# nrf54lv10a_enga_application register map
Vendor: Nordic Semiconductor; Series: nrf54l; File version: 1
CPU: CM33 r0p4, little endian, MPU, FPU, 3 interrupt priority bits, 270 interrupts, 4 SAU regions
Registers are 32-bit, read-write, reset 0x0 unless marked. A register's access mark holds for its fields unless they carry their own. Offsets are from the block's base; [hi:lo] are bit positions; lines under a group give offsets from that group; {n}, {i} and the like mark numbered series; 'fields as' and 'values as' point back to an identical list.

## GLOBAL_PPIB00_NS — PPIB APB registers 0
Base 0x40044000
Same registers: GLOBAL_PPIB01_NS 0x40045000, GLOBAL_PPIB10_NS 0x40083000, GLOBAL_PPIB11_NS 0x40084000, GLOBAL_PPIB20_NS 0x400C3000, GLOBAL_PPIB21_NS 0x400C4000, GLOBAL_PPIB22_NS 0x400C5000, GLOBAL_PPIB30_NS 0x40103000, GLOBAL_PPIB00_S 0x50044000, GLOBAL_PPIB01_S 0x50045000, GLOBAL_PPIB10_S 0x50083000, GLOBAL_PPIB11_S 0x50084000, GLOBAL_PPIB20_S 0x500C3000, GLOBAL_PPIB21_S 0x500C4000, GLOBAL_PPIB22_S 0x500C5000, GLOBAL_PPIB30_S 0x50103000
{0x0+4i} TASKS_SEND[{i}] (i=0..31) wo — Description collection: This task is unused, but the PPIB provides the SUBSCRIBE task to connect SEND [n] task.
  [0] TASKS_SEND — This task is unused, but the PPIB provides the SUBSCRIBE task to connect SEND [n] task.
    1=Trigger task
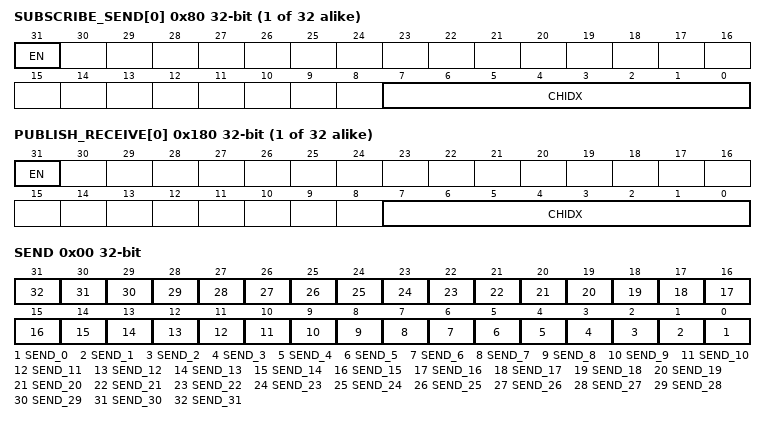
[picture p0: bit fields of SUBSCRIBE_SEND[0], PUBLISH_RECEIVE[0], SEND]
{0x80+4i} SUBSCRIBE_SEND[{i}] (i=0..31) — Description collection: Subscribe configuration for task SEND[n]
  [31] EN
    0=Disabled (Disable subscription); 1=Enabled (Enable subscription)
  [7:0] CHIDX — DPPI channel that task SEND[n] will subscribe to
{0x100+4i} EVENTS_RECEIVE[{i}] (i=0..31) — Description collection: This event is unused, but the PPIB provides the PUBLISH event to connect RECEIVE [n] event.
  [0] EVENTS_RECEIVE — This event is unused, but the PPIB provides the PUBLISH event to connect RECEIVE [n] event.
    0=NotGenerated (Event not generated); 1=Generated (Event generated)
{0x180+4i} PUBLISH_RECEIVE[{i}] (i=0..31) — Description collection: Publish configuration for event RECEIVE[n]
  [31] EN
    0=Disabled (Disable publishing); 1=Enabled (Enable publishing)
  [7:0] CHIDX — DPPI channel that event RECEIVE[n] will publish to
0x400 OVERFLOW group — Unspecified
  0x00 SEND — The task overflow for SEND tasks using SUBSCRIBE_SEND. Write 0 to clear.
    [all] fields
      1=Overflow (Task overflow is happened.); 0=NoOverflow (Task overflow is not happened.)
    [n] SEND_{n} (n=0..31) — The status for tasks overflow at SUBSCRIBE_SEND[{n}].

## GLOBAL_KMU_S — Key management unit
Base 0x50049000
0x00 TASKS_PROVISION wo — Provision key slot
  [0] TASKS_PROVISION
    1=Trigger task
0x04 TASKS_PUSH wo — Push key slot
  [0] TASKS_PUSH
    1=Trigger task
0x08 TASKS_REVOKE wo — Revoke key slot
  [0] TASKS_REVOKE
    1=Trigger task
0x0C TASKS_READMETADATA wo — Read key slot metadata into METADATA register
  [0] TASKS_READMETADATA
    1=Trigger task
0x10 TASKS_PUSHBLOCK wo — Block only the PUSH operation of a key slot, preventing the key slot from being PUSHED until next reset. The task is kept for backwards compatibility.
  [0] TASKS_PUSHBLOCK
    1=Trigger task
0x14 TASKS_BLOCK wo — Block the PROVISION, PUSH, and REVOKE operations of a key slot, preventing the key slot from being PROVISIONED, PUSHED, or REVOKED until next reset
  [0] TASKS_BLOCK
    1=Trigger task
0x100 EVENTS_PROVISIONED — Key slot successfully provisioned
  [0] EVENTS_PROVISIONED
    0=NotGenerated (Event not generated); 1=Generated (Event generated)
0x104 EVENTS_PUSHED — Key slot successfully pushed
  [0] EVENTS_PUSHED
    values as EVENTS_PROVISIONED.EVENTS_PROVISIONED
0x108 EVENTS_REVOKED — Key slot has been revoked and can no longer be used
  [0] EVENTS_REVOKED
    values as EVENTS_PROVISIONED.EVENTS_PROVISIONED
0x10C EVENTS_ERROR — Error generated during PROVISION, PUSH, READMETADATA or REVOKE operations. Triggering the PROVISION, PUSH and REVOKE tasks on a BLOCKED keyslot will also generate this event.
  [0] EVENTS_ERROR
    values as EVENTS_PROVISIONED.EVENTS_PROVISIONED
0x110 EVENTS_METADATAREAD — Key slot metadata has been read into METADATA register
  [0] EVENTS_METADATAREAD
    values as EVENTS_PROVISIONED.EVENTS_PROVISIONED
0x114 EVENTS_PUSHBLOCKED — The PUSHBLOCK operation was successful. The event is kept for backwards compatibility.
  [0] EVENTS_PUSHBLOCKED
    values as EVENTS_PROVISIONED.EVENTS_PROVISIONED
0x118 EVENTS_BLOCKED — The BLOCK operation was successful
  [0] EVENTS_BLOCKED
    values as EVENTS_PROVISIONED.EVENTS_PROVISIONED
0x400 STATUS ro — KMU status register
  [0] STATUS — KMU status
    0=Ready (KMU is ready for new operation); 1=Busy (KMU is busy, an operation is in progress)
0x500 KEYSLOT — Select key slot to operate on
  [7:0] ID — Select key slot ID to provision, push, read METADATA, revoke or block when the corresponding task is triggered.
0x504 SRC — Source address for provisioning
  [31:0] SRC — Source address for TASKS_PROVISION.
0x508 METADATA — Key slot metadata as read by TASKS_READMETADATA.
  [31:0] METADATA — Read metadata.

## Notices in the file
Copyright (c) 2010 - 2025, Nordic Semiconductor ASA
All rights reserved.
Redistribution and use in source and binary forms, with or without modification,
are permitted provided that the following conditions are met:
1. Redistributions of source code must retain the above copyright notice, this
list of conditions and the following disclaimer.
2. Redistributions in binary form, except as embedded into a Nordic
Semiconductor ASA integrated circuit in a product or a software update for
such product, must reproduce the above copyright notice, this list of
conditions and the following disclaimer in the documentation and/or other
materials provided with the distribution.
3. Neither the name of Nordic Semiconductor ASA nor the names of its
contributors may be used to endorse or promote products derived from this
software without specific prior written permission.
4. This software, with or without modification, must only be used with a
Nordic Semiconductor ASA integrated circuit.
5. Any software provided in binary form under this license must not be reverse
engineered, decompiled, modified and/or disassembled.
THIS SOFTWARE IS PROVIDED BY NORDIC SEMICONDUCTOR ASA "AS IS" AND ANY EXPRESS
OR IMPLIED WARRANTIES, INCLUDING, BUT NOT LIMITED TO, THE IMPLIED WARRANTIES
OF MERCHANTABILITY, NONINFRINGEMENT, AND FITNESS FOR A PARTICULAR PURPOSE ARE
DISCLAIMED. IN NO EVENT SHALL NORDIC SEMICONDUCTOR ASA OR CONTRIBUTORS BE
LIABLE FOR ANY DIRECT, INDIRECT, INCIDENTAL, SPECIAL, EXEMPLARY, OR
CONSEQUENTIAL DAMAGES (INCLUDING, BUT NOT LIMITED TO, PROCUREMENT OF SUBSTITUTE
GOODS OR SERVICES; LOSS OF USE, DATA, OR PROFITS; OR BUSINESS INTERRUPTION)
HOWEVER CAUSED AND ON ANY THEORY OF LIABILITY, WHETHER IN CONTRACT, STRICT
LIABILITY, OR TORT (INCLUDING NEGLIGENCE OR OTHERWISE) ARISING IN ANY WAY OUT
OF THE USE OF THIS SOFTWARE, EVEN IF ADVISED OF THE POSSIBILITY OF SUCH DAMAGE.
